# SIM3C164_B register map
File version: 1
CPU: 
Registers are 32-bit, read-write, reset 0x0 unless marked. A register's access mark holds for its fields unless they carry their own. Offsets are from the block's base; [hi:lo] are bit positions; {n}, {i} and the like mark numbered series; 'fields as' and 'values as' point back to an identical list.

## PBHD_4
Base 0x4002A3C0
0x00 PB reset 0x3F — Output Latch
  [5:0] PB — Output Latch.
0x10 PBPIN — Pin Value
  [5:0] PBPIN ro — Pin Value.
0x20 PBMDSEL reset 0x3F — Mode Select
  [5:0] PBMDSEL — Mode Select.
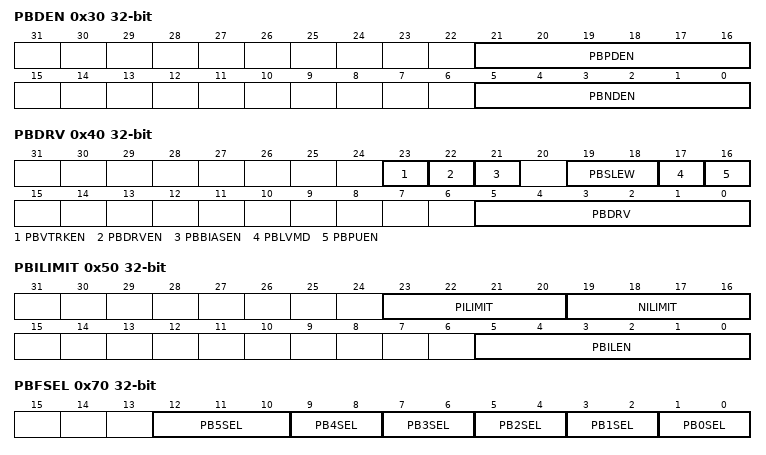
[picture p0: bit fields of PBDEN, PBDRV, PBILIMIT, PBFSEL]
0x30 PBDEN — Driver Enable
  [21:16] PBPDEN — Port Bank P-Channel Driver Enable.
  [5:0] PBNDEN — Port Bank N-Channel Driver Enable.
0x40 PBDRV — Drive Strength
  [23] PBVTRKEN — Port Voltage Supply Tracking Enable.
    0=DISABLED (Disable VIOHD tracking.); 1=ENABLED (Enable VIOHD tracking.)
  [22] PBDRVEN — Port Drive Enable.
    0=DISABLED (Disable the port drivers.); 1=ENABLED (Enable the port drivers.)
  [21] PBBIASEN — Port Bias Enable.
    0=DISABLED (Disable the biasing to the port pins.); 1=ENABLED (Enable the biasing to the port pins.)
  [19:18] PBSLEW — Port Slew Control.
    0=FASTEST (Select the fastest transition speed for this port bank.); 1=FASTER (Select the faster transition speed for this port bank.); 2=SLOWER (Select the slower transition speed for this port bank.); 3=SLOWEST (Select the slowest transition speed for this port bank.)
  [17] PBLVMD — Port Low Voltage Mode.
    0=NORMAL (Port configured for normal mode.); 1=LOW (Port configured for low power mode.)
  [16] PBPUEN — Port Bank Weak Pull-up Enable.
    0=DISABLED (Disable weak pull-ups for this port.); 1=ENABLED (Enable weak pull-ups for this port.)
  [5:0] PBDRV — Drive Strength.
0x50 PBILIMIT — Current Limit
  [23:20] PILIMIT — P-Channel Current Limit.
    {v}=MODE{v} (Set source limit to mode {v}.) (v=0..15)
  [19:16] NILIMIT — N-Channel Current Limit.
    {v}=MODE{v} (Set sink limit to mode {v}.) (v=0..15)
  [5:0] PBILEN — Current Limit Enable.
0x70 PBFSEL — Function Select
  [12:10] PB5SEL — Port Bank n.5 Function Select.
    0=GPIO (Pin configured for GPIO.); 1=PMLS (Pin configured for Port Mapped Level Shift.); 2=EPCA0 (Pin configured for EPCA0 output.); 3=UART1 (Pin configured for UART1 CTS.); 4=LPTIMER0 (Pin configured for LPTIMER0 toggle output.)
  [9:8] PB4SEL — Port Bank n.4 Function Select.
    0=GPIO (Pin configured for GPIO.); 1=PMLS (Pin configured for Port Mapped Level Shift.); 2=EPCA0 (Pin configured for EPCA0 output.); 3=UART1 (Pin configured for UART1 RTS.)
  [7:6] PB3SEL — Port Bank n.3 Function Select.
    0=GPIO (Pin configured for GPIO.); 1=PMLS (Pin configured for Port Mapped Level Shift.); 2=EPCA0 (Pin configured for EPCA0 output.); 3=UART1 (Pin configured for UART1 RX.)
  [5:4] PB2SEL — Port Bank n.2 Function Select.
    0=GPIO (Pin configured for GPIO.); 1=PMLS (Pin configured for Port Mapped Level Shift.); 2=EPCA0 (Pin configured for EPCA0 output.); 3=UART1 (Pin configured for UART1 TX.)
  [3:2] PB1SEL — Port Bank n.1 Function Select.
    0=GPIO (Pin configured for GPIO.); 1=PMLS (Pin configured for Port Mapped Level Shift.); 2=EPCA0 (Pin configured for EPCA0 output.)
  [1:0] PB0SEL — Port Bank n.0 Function Select.
    values as PB1SEL
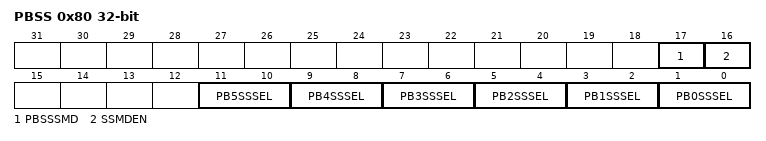
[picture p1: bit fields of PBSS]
0x80 PBSS — Safe State Control
  [17] PBSSSMD — Safe State Signal Mode.
    0=DEGLITCH (Enable deglitching on the kill signal input. The kill signal must be asserted for two APB clocks to be recognized.); 1=IMMEDIATE (Disable deglitching on the kill signal input. The kill signal will take immediate effect.)
  [16] SSMDEN — Enter Safe State Mode.
    0=DISABLED (Disable Safe State.); 1=ENABLED (Enter Safe State. Each PBn.x pin will enter the states defined by PBxSSSEL.)
  [11:10] PB5SSSEL — Port Bank n.5 Safe State Select.
    0=HIZ (Place PBn.5 in a High Impedance state.); 1=HIGH (Drive PBn.5 High.); 2=LOW (Drive PBn.5 Low.); 3=DISABLED (Ignore the safe state signal (weak pull-ups disabled).)
  [9:8] PB4SSSEL — Port Bank n.4 Safe State Select.
    0=HIZ (Place PBn.4 in a High Impedance state.); 1=HIGH (Drive PBn.4 High.); 2=LOW (Drive PBn.4 Low.); 3=DISABLED (Ignore the safe state signal (weak pull-ups disabled).)
  [7:6] PB3SSSEL — Port Bank n.3 Safe State Select.
    0=HIZ (Place PBn.3 in a High Impedance state.); 1=HIGH (Drive PBn.3 High.); 2=LOW (Drive PBn.3 Low.); 3=DISABLED (Ignore the safe state signal (weak pull-ups disabled).)
  [5:4] PB2SSSEL — Port Bank n.2 Safe State Select.
    0=HIZ (Place PBn.2 in a High Impedance state.); 1=HIGH (Drive PBn.2 High.); 2=LOW (Drive PBn.2 Low.); 3=DISABLED (Ignore the safe state signal (weak pull-ups disabled).)
  [3:2] PB1SSSEL — Port Bank n.1 Safe State Select.
    0=HIZ (Place PBn.1 in a High Impedance state.); 1=HIGH (Drive PBn.1 High.); 2=LOW (Drive PBn.1 Low.); 3=DISABLED (Ignore the safe state signal (weak pull-ups disabled).)
  [1:0] PB0SSSEL — Port Bank n.0 Safe State Select.
    0=HIZ (Place PBn.0 in a High Impedance state.); 1=HIGH (Drive PBn.0 High.); 2=LOW (Drive PBn.0 Low.); 3=DISABLED (Ignore the safe state signal (weak pull-ups disabled).)
0x90 PBLOCK reset 0x3F — Lock Control
  [5:0] PBLOCK — Port Bank Lock.
